AUTOSAR XML (schema 3.1.4)
package /SYSTEM
  system New_Element_16: fibex-element=[MONonCAN_Endurance_V314, S_STD_0x200_S1, F_STD_0x200, S_STD_0x200_PDU, AUT, REF_ECU, S_STD_0x200_S2, S_STD_0x200_S3, S_STD_0x200_S4, S_STD_0x200_S5, S_STD_0x200_S6, S_STD_0x200_S7, S_STD_0x200_S8, S_STD_0x200_S12, S_STD_0x200_S16, F_STD_0x201, F_STD_0x202, F_STD_0x203, F_STD_0x204, F_STD_0x205, F_STD_0x206, F_STD_0x207, F_STD_0x208, F_EXT_0x1000000, F_EXT_0x1000001, F_EXT_0x1000002, F_EXT_0x1000003, F_EXT_0x1000004, F_EXT_0x1000005, F_EXT_0x1000006, F_EXT_0x1000007, F_EXT_0x1000008, S_STD_0x201_S8, S_STD_0x202_S16, S_STD_0x203_S24, S_STD_0x204_S32, S_STD_0x205_S32, S_STD_0x205_S8, S_STD_0x206_S32, S_STD_0x206_S16, S_STD_0x207_S32, S_STD_0x207_S24, S_STD_0x208_1_S32, S_STD_0x208_2_S32, F_STD_0x201_PDU, F_STD_0x202_PDU, F_STD_0x203_PDU, F_STD_0x204_PDU, F_STD_0x205_PDU, F_STD_0x206_PDU, F_STD_0x207_PDU, F_STD_0x208_PDU, S_EXT_0x1000000_S1, S_EXT_0x1000000_S2, S_EXT_0x1000000_S3, S_EXT_0x1000000_S4, S_EXT_0x1000000_S5, S_EXT_0x1000000_S6, S_EXT_0x1000000_S7, S_EXT_0x1000000_S8, S_EXT_0x1000001_S8, S_EXT_0x1000000_S12, S_EXT_0x1000000_S16, F_EXT_0x1000000_PDU, F_EXT_0x1000001_PDU, S_EXT_0x1000002_S16, S_EXT_0x1000003_S24, S_EXT_0x1000004_S32, S_EXT_0x1000005_S32, S_EXT_0x1000005_S8, S_EXT_0x1000006_S32, S_EXT_0x1000006_S16, S_EXT_0x1000007_S32, S_EXT_0x1000007_S24, S_EXT_0x1000008_1_S32, S_EXT_0x1000008_2_S32, F_EXT_0x1000002_PDU, F_EXT_0x1000003_PDU, F_EXT_0x1000004_PDU, F_EXT_0x1000005_PDU, F_EXT_0x1000006_PDU, F_EXT_0x1000007_PDU, F_EXT_0x1000008_PDU]
package /MONonCAN_Endurance_V314
  can cluster MONonCAN_Endurance_V314: nm-node-detection-enabled=false, nm-node-id-enabled=false, nm-repeat-message-support=false, protocol-name=CAN, speed=1000000
    physical channel CANChannel
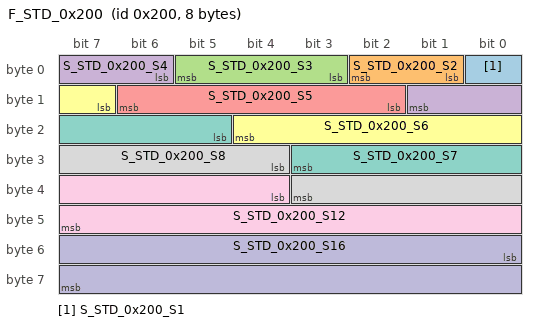
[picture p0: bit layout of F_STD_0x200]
      frame F_STD_0x200: id 0x200, from AUT, frame-length=8, can-addressing-mode=STANDARD
        pdu S_STD_0x200_PDU: length=64
          signal S_STD_0x200_S1: start 0, 1 bit, little-endian
          signal S_STD_0x200_S2: start 1, 2 bit, little-endian
          signal S_STD_0x200_S3: start 3, 3 bit, little-endian
          signal S_STD_0x200_S4: start 6, 4 bit, little-endian
          signal S_STD_0x200_S5: start 10, 5 bit, little-endian
          signal S_STD_0x200_S6: start 15, 6 bit, little-endian
          signal S_STD_0x200_S7: start 21, 7 bit, little-endian
          signal S_STD_0x200_S8: start 28, 8 bit, little-endian
          signal S_STD_0x200_S12: start 36, 12 bit, little-endian
          signal S_STD_0x200_S16: start 48, 16 bit, little-endian, data-type=Type_79660689737e4cd194c5e9b76b5c59fd
      frame F_STD_0x201: id 0x201, from AUT, frame-length=1, can-addressing-mode=STANDARD
        pdu F_STD_0x201_PDU: length=8
          signal S_STD_0x201_S8: start 0, 8 bit, little-endian
      frame F_STD_0x202: id 0x202, from AUT, frame-length=2, can-addressing-mode=STANDARD
        pdu F_STD_0x202_PDU: length=16
          signal S_STD_0x202_S16: start 0, 16 bit, little-endian
      frame F_STD_0x203: id 0x203, from AUT, frame-length=3, can-addressing-mode=STANDARD
        pdu F_STD_0x203_PDU: length=24
          signal S_STD_0x203_S24: start 0, 24 bit, little-endian
      frame F_STD_0x204: id 0x204, from AUT, frame-length=4, can-addressing-mode=STANDARD
        pdu F_STD_0x204_PDU: length=32
          signal S_STD_0x204_S32: start 0, 32 bit, little-endian
      frame F_STD_0x205: id 0x205, from AUT, frame-length=5, can-addressing-mode=STANDARD
        pdu F_STD_0x205_PDU: length=40
          signal S_STD_0x205_S32: start 0, 32 bit, little-endian
          signal S_STD_0x205_S8: start 32, 8 bit, little-endian
      frame F_STD_0x206: id 0x206, from AUT, frame-length=6, can-addressing-mode=STANDARD
        pdu F_STD_0x206_PDU: length=48
          signal S_STD_0x206_S32: start 0, 32 bit, little-endian
          signal S_STD_0x206_S16: start 32, 16 bit, little-endian
      frame F_STD_0x207: id 0x207, from AUT, frame-length=7, can-addressing-mode=STANDARD
        pdu F_STD_0x207_PDU: length=56
          signal S_STD_0x207_S32: start 0, 32 bit, little-endian
          signal S_STD_0x207_S24: start 32, 24 bit, little-endian
      frame F_STD_0x208: id 0x208, from AUT, frame-length=8, can-addressing-mode=STANDARD
        pdu F_STD_0x208_PDU: length=64
          signal S_STD_0x208_1_S32: start 0, 32 bit, little-endian, data-type=Type_c7a4a22fc4f74df2a008f8a4261e82a6
          signal S_STD_0x208_2_S32: start 32, 32 bit, little-endian
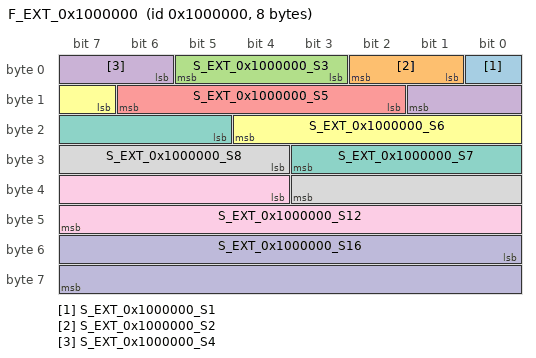
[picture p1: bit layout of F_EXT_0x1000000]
      frame F_EXT_0x1000000: id 0x1000000, from AUT, frame-length=8, can-addressing-mode=EXTENDED
        pdu F_EXT_0x1000000_PDU: length=64
          signal S_EXT_0x1000000_S1: start 0, 1 bit, little-endian
          signal S_EXT_0x1000000_S2: start 1, 2 bit, little-endian
          signal S_EXT_0x1000000_S3: start 3, 3 bit, little-endian
          signal S_EXT_0x1000000_S4: start 6, 4 bit, little-endian
          signal S_EXT_0x1000000_S5: start 10, 5 bit, little-endian
          signal S_EXT_0x1000000_S6: start 15, 6 bit, little-endian
          signal S_EXT_0x1000000_S7: start 21, 7 bit, little-endian
          signal S_EXT_0x1000000_S8: start 28, 8 bit, little-endian
          signal S_EXT_0x1000000_S12: start 36, 12 bit, little-endian
          signal S_EXT_0x1000000_S16: start 48, 16 bit, little-endian
      frame F_EXT_0x1000001: id 0x1000001, from AUT, frame-length=1, can-addressing-mode=EXTENDED
        pdu F_EXT_0x1000001_PDU: length=8
          signal S_EXT_0x1000001_S8: start 0, 8 bit, little-endian
      frame F_EXT_0x1000002: id 0x1000002, from AUT, frame-length=2, can-addressing-mode=EXTENDED
        pdu F_EXT_0x1000002_PDU: length=16
          signal S_EXT_0x1000002_S16: start 0, 16 bit, little-endian
      frame F_EXT_0x1000003: id 0x1000003, from AUT, frame-length=3, can-addressing-mode=EXTENDED
        pdu F_EXT_0x1000003_PDU: length=24
          signal S_EXT_0x1000003_S24: start 0, 24 bit, little-endian
      frame F_EXT_0x1000004: id 0x1000004, from AUT, frame-length=4, can-addressing-mode=EXTENDED
        pdu F_EXT_0x1000004_PDU: length=32
          signal S_EXT_0x1000004_S32: start 0, 32 bit, little-endian
      frame F_EXT_0x1000005: id 0x1000005, from AUT, frame-length=5, can-addressing-mode=EXTENDED
        pdu F_EXT_0x1000005_PDU: length=40
          signal S_EXT_0x1000005_S32: start 0, 32 bit, little-endian
          signal S_EXT_0x1000005_S8: start 32, 8 bit, little-endian
      frame F_EXT_0x1000006: id 0x1000006, from AUT, frame-length=6, can-addressing-mode=EXTENDED
        pdu F_EXT_0x1000006_PDU: length=48
          signal S_EXT_0x1000006_S32: start 0, 32 bit, little-endian
          signal S_EXT_0x1000006_S16: start 32, 16 bit, little-endian
      frame F_EXT_0x1000007: id 0x1000007, from AUT, frame-length=7, can-addressing-mode=EXTENDED
        pdu F_EXT_0x1000007_PDU: length=56
          signal S_EXT_0x1000007_S32: start 0, 32 bit, little-endian
          signal S_EXT_0x1000007_S24: start 32, 24 bit, little-endian
      frame F_EXT_0x1000008: id 0x1000008, from AUT, frame-length=8, can-addressing-mode=EXTENDED
        pdu F_EXT_0x1000008_PDU: length=64
          signal S_EXT_0x1000008_1_S32: start 0, 32 bit, little-endian
          signal S_EXT_0x1000008_2_S32: start 32, 32 bit, little-endian
package /MONonCAN_Endurance_V314/I_SIGNALS
  integer type Type_79660689737e4cd194c5e9b76b5c59fd: compu {phys=raw*2+2 for raw 0..65535}
  integer type Type_c7a4a22fc4f74df2a008f8a4261e82a6: compu {phys=raw*2+4 for raw 0..-1}
package /ECU_INSTANCES
  ecu instance AUT: diagnostic-address=0, sleep-mode-supported=false, wake-up-over-bus-supported=false
    can communication controller Controller_AUT: wake-up-by-controller-supported=false
    communication connector Connector_AUT: channel=CANChannel, comm-controller=Controller_AUT
  ecu instance REF_ECU: diagnostic-address=0, sleep-mode-supported=false, wake-up-over-bus-supported=false
    can communication controller Controller_REF_ECU: wake-up-by-controller-supported=false
    communication connector Connector_REF_ECU: channel=CANChannel, comm-controller=Controller_REF_ECU
